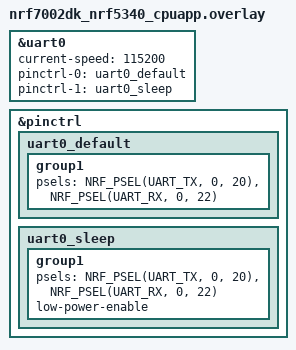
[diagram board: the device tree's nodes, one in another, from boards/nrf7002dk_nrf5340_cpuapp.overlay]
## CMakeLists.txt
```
cmake_minimum_required(VERSION 3.20.0)

find_package(Zephyr REQUIRED HINTS $ENV{ZEPHYR_BASE})
project(nrf7002_sniffer)

# Dodajemy pliki źródłowe
target_sources(app PRIVATE 
    src/main.cpp 
    src/wifi_scanner.c 
    src/ble_scanner.c
)

# Nagłówki
target_include_directories(app PRIVATE 
    ${CMAKE_CURRENT_SOURCE_DIR}/src 
    ${CMAKE_CURRENT_SOURCE_DIR}/../common/include
)

# Biblioteka OpenDroneID
add_subdirectory(${CMAKE_CURRENT_SOURCE_DIR}/../common/lib/opendroneid build_opendroneid)
target_link_libraries(app PRIVATE opendroneid_lib)
```

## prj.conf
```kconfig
# --- Konfiguracja Systemowa ---
CONFIG_CPP=y
CONFIG_STD_CPP20=y
CONFIG_NEWLIB_LIBC=y
CONFIG_FPU=y

# --- Bluetooth ---
CONFIG_BT=y
CONFIG_BT_OBSERVER=y
CONFIG_BT_EXT_ADV=y

# To jest "magiczna" flaga dla nRF5340, która włącza komunikację z rdzeniem sieciowym
# i automatycznie ustawi wszystkie potrzebne parametry (w tym HCI)
CONFIG_BT_HCI_IPC=y

# Opcjonalne, ale pomocne
CONFIG_BT_DEVICE_NAME="nRF7002_Sniffer"

# --- Wi-Fi (nRF7002 + WPA Supplicant) ---
CONFIG_WIFI=y
CONFIG_WIFI_NRF700X=y
CONFIG_WPA_SUPP=y
CONFIG_NET_L2_WIFI_MGMT=y

CONFIG_WIFI_MGMT_RAW_SCAN_RESULTS=y
CONFIG_WIFI_MGMT_RAW_SCAN_RESULT_LENGTH=512

# Włączamy zaawansowane funkcje, które widnieją w Twoim Kconfig
CONFIG_WPA_SUPP_ADVANCED_FEATURES=y
CONFIG_WPA_SUPP_AP=y

# Networking
CONFIG_NETWORKING=y
CONFIG_NET_NATIVE=y
CONFIG_NET_L2_ETHERNET=y
CONFIG_NET_MGMT=y
CONFIG_NET_MGMT_EVENT=y

# Pamięć (zwiększona zgodnie z Twoim Kconfig dla trybu AP/Supplicant)
CONFIG_COMMON_LIBC_MALLOC_ARENA_SIZE=40000
CONFIG_MAIN_STACK_SIZE=8192
CONFIG_SYSTEM_WORKQUEUE_STACK_SIZE=4096
CONFIG_NET_MGMT_EVENT_STACK_SIZE=4200

# --- Komunikacja ---
CONFIG_SERIAL=y
CONFIG_UART_ASYNC_API=y
CONFIG_PRINTK=y

CONFIG_WIFI_MGMT_SCAN_SSID_FILT_MAX=1
CONFIG_MAIN_STACK_SIZE=8192
```

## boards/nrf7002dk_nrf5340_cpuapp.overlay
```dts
&uart0 {
    status = "okay";
    current-speed = <115200>;
    /* Musimy podać oba stany, bo tego oczekuje definicja nRF5340 */
    pinctrl-0 = <&uart0_default>;
    pinctrl-1 = <&uart0_sleep>;
    pinctrl-names = "default", "sleep";
};

&pinctrl {
    uart0_default: uart0_default {
        group1 {
            psels = <NRF_PSEL(UART_TX, 0, 20)>,
                    <NRF_PSEL(UART_RX, 0, 22)>;
        };
    };

    /* Dodajemy definicję dla trybu uśpienia (wymagane) */
    uart0_sleep: uart0_sleep {
        group1 {
            psels = <NRF_PSEL(UART_TX, 0, 20)>,
                    <NRF_PSEL(UART_RX, 0, 22)>;
            low-power-enable;
        };
    };
};
```

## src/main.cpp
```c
#include <zephyr/kernel.h>
#include <zephyr/drivers/uart.h>
#include <zephyr/sys/printk.h>
#include <zephyr/bluetooth/bluetooth.h> // DODAJ TO KONIECZNIE
#include <math.h> 
#include "inter_board_protocol.h"
#include "drone_id_types.hpp"

extern "C" {
    int start_wifi_sniffer(void);
    int start_ble_sniffer(void);
}

static const struct device *uart_brain = DEVICE_DT_GET(DT_NODELABEL(uart0));
K_MUTEX_DEFINE(uart_mutex);

/**
 * @brief Szacowanie odległości na podstawie RSSI.
 * @note To jest model log-distance path loss.
 */
float estimate_distance(int8_t rssi) {
    // Parametry można dostroić doświadczalnie
    float rssi_at_1m = -38.0f; // Typowa wartość dla drona 1m od odbiornika
    float n = 2.2f;            // Współczynnik propagacji (2.0 = próżnia)
    
    if (rssi >= 0) return 0.0f;
    return powf(10.0f, (rssi_at_1m - (float)rssi) / (10.0f * n));
}

/**
 * @brief Funkcja wysyłająca dane do głównego procesora (Brain) przez UART.
 */
extern "C" void send_to_brain(DroneDiscoveryData *data) {
    // 1. Obliczamy zmienne pomocnicze RAZ na początku funkcji
    float dist = estimate_distance(data->rssi);
    const char *proto = (data->protocol_type < 2) ? "Wi-Fi" : "BLE";

    // 2. LOGOWANIE DO KONSOLI (DEBUG)
    // To tutaj decydujesz, jak log wygląda w terminalu
    if (data->latitude != 0) {
        printk("[%s] DRONE DETECTED! | SN: %s | GPS: %.6f, %.6f | Alt: %.1fm | Dist: %.1fm\n",
               proto, data->serial_number, 
               (double)data->latitude / 10000000.0, 
               (double)data->longitude / 10000000.0,
               (double)data->altitude_msl / 100.0, 
               (double)dist);
    } else {
        // Log dla zwykłych sygnałów (tutaj będzie widać Twojego producenta i MAC)
        printk("[%s] Signal | ID: %s | RSSI: %d dBm | Dist: %.1fm\n", 
               proto, data->serial_number, data->rssi, (double)dist);
    }

    // 3. WYSYŁKA BINARNA DO PROCESORA "BRAIN" (UART)
    IpcHeader header = {
        .magic = PROTOCOL_MAGIC_BYTE,
        .type = MSG_TYPE_DRONE_DATA,
        .length = sizeof(DroneDiscoveryData)
    };
    
    uint8_t checksum = calculate_checksum((const uint8_t*)data, sizeof(DroneDiscoveryData));
    
    // if (k_mutex_lock(&uart_mutex, K_MSEC(100)) == 0) {
    //     uart_tx(uart_brain, (uint8_t*)&header, sizeof(header), SYS_FOREVER_US);
    //     k_busy_wait(1000); 
    //     uart_tx(uart_brain, (uint8_t*)data, sizeof(DroneDiscoveryData), SYS_FOREVER_US);
    //     k_busy_wait(2000);
    //     uart_tx(uart_brain, &checksum, 1, SYS_FOREVER_US);
    //     k_mutex_unlock(&uart_mutex);
    // }
}

int main(void) {
    k_msleep(1000);
    printk("\n--- nRF7002 RemoteID Sniffer v2.2 ---\n");

    if (!device_is_ready(uart_brain)) {
        printk("BŁĄD: UART brain nie jest gotowy!\n");
        return -1;
    }

    // Inicjalizacja Bluetooth przed snifferem!
    int bt_err = bt_enable(NULL);
    if (bt_err) {
        printk("BŁĄD: Inicjalizacja BT nieudana: %d\n", bt_err);
    } else {
        printk("Bluetooth OK.\n");
    }

    start_ble_sniffer();
    start_wifi_sniffer();

    printk("Skanowanie rozpoczęte...\n");

    while (1) { k_msleep(5000); }
}
```

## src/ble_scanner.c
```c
#include <zephyr/bluetooth/bluetooth.h>
#include <zephyr/bluetooth/hci.h>
#include <zephyr/sys/printk.h>
#include <stdio.h>
#include <string.h>
#include "drone_id_types.hpp"
#include <opendroneid.h>

extern void send_to_brain(struct DroneDiscoveryData *data);

// Musimy ją mieć też tutaj (lub w osobnym pliku .h)
static const char* identify_manufacturer(const uint8_t *mac) {
    // 1. Bit losowości - sprawdzamy na końcu, żeby najpierw spróbować dopasować realne OUI
    // (Niektóre firmy używają wielu zakresów, w tym nietypowych)

    // --- DRONY I KONTROLERY ---
    if (mac[0] == 0x60 && mac[1] == 0x60 && mac[2] == 0x1F) return "DJI";
    if (mac[0] == 0x00 && mac[1] == 0x26 && mac[2] == 0x7E) return "DJI";
    if (mac[0] == 0x34 && mac[1] == 0xD2 && mac[2] == 0x62) return "DJI (Mavic)";
    if (mac[0] == 0x00 && mac[1] == 0xE0 && mac[2] == 0x4C) return "DJI (Realtek-Base)";
    if (mac[0] == 0x00 && mac[1] == 0x12 && mac[2] == 0x1C) return "Parrot";
    if (mac[0] == 0x90 && mac[1] == 0x03 && mac[2] == 0xB7) return "Parrot (Skycontroller)";
    if (mac[0] == 0x00 && mac[1] == 0x0B && mac[2] == 0xE5) return "Autel Robotics";
    if (mac[0] == 0x08 && mac[1] == 0xD5 && mac[2] == 0x39) return "FIMI (Xiaomi)";
    if (mac[0] == 0x40 && mac[1] == 0x15 && mac[2] == 0xFF) return "Hubsan";
    if (mac[0] == 0x10 && mac[1] == 0x04 && mac[2] == 0xB8) return "Skydio";
    if (mac[0] == 0x04 && mac[1] == 0xEE && mac[2] == 0x03) return "Yuneec";

    // --- SPRZĘT MOBILNY / TELEFONY ---
    // Apple (częste zakresy)
    if (mac[0] == 0xAC && mac[1] == 0x3C && mac[2] == 0x0B) return "Apple (iPhone)";
    if (mac[0] == 0xF0 && mac[1] == 0x18 && mac[2] == 0x98) return "Apple";
    if (mac[0] == 0x8C && mac[1] == 0x85 && mac[2] == 0x90) return "Apple";
    
    // Samsung
    if (mac[0] == 0x3E && mac[1] == 0x36 && mac[2] == 0xF0) return "Samsung";
    if (mac[0] == 0x50 && mac[1] == 0x85 && mac[2] == 0x69) return "Samsung";
    if (mac[0] == 0x24 && mac[1] == 0xFC && mac[2] == 0xE5) return "Samsung";

    // Xiaomi / Huawei / Oppo
    if (mac[0] == 0x64 && mac[1] == 0x09 && mac[2] == 0x80) return "Xiaomi";
    if (mac[0] == 0x28 && mac[1] == 0x6D && mac[2] == 0xCD) return "Xiaomi";
    if (mac[0] == 0x40 && mac[1] == 0x4D && mac[2] == 0x7F) return "Huawei";
    if (mac[0] == 0x34 && mac[1] == 0xCE && mac[2] == 0x00) return "Huawei";

    // --- MODUŁY I IOT (Dla dłubaczy dornów DIY) ---
    if (mac[0] == 0x24 && mac[1] == 0xA5 && mac[2] == 0x2C) return "Espressif (ESP32)";
    if (mac[0] == 0x30 && mac[1] == 0xAE && mac[2] == 0xA4) return "Espressif (ESP32)";
    if (mac[0] == 0xDC && mac[1] == 0xA6 && mac[2] == 0x32) return "Raspberry Pi";
    if (mac[0] == 0xB8 && mac[1] == 0x27 && mac[2] == 0xEB) return "Raspberry Pi";
    if (mac[0] == 0xE8 && mac[1] == 0x31 && mac[2] == 0xCD) return "Linksys/Cisco";
    if (mac[0] == 0x00 && mac[1] == 0x50 && mac[2] == 0x43) return "Marvell (często drony)";

    // --- CHECK BITU LOSOWOŚCI (LAA) ---
    if ((mac[0] & 0x02) == 0x02) return "Mobile/Random";

    return "Unknown";
}

struct ble_parse_context {
    struct DroneDiscoveryData *drone_data;
    bool name_found;
    bool rid_found;
};

static bool ble_ad_cb(struct bt_data *data, void *user_data) {
    struct ble_parse_context *ctx = (struct ble_parse_context *)user_data;

    // 1. Nazwa urządzenia (Active Scan Response)
    if ((data->type == BT_DATA_NAME_COMPLETE || data->type == BT_DATA_NAME_SHORTENED)) {
        char temp_name[16];
        size_t name_len = MIN(data->data_len, sizeof(temp_name) - 1);
        memcpy(temp_name, data->data, name_len);
        temp_name[name_len] = '\0';
        
        // Bezpieczne łączenie: Nazwa + to co już jest w serial_number (np. końcówka MAC)
        // Zakładamy, że w serial_number mamy już "Producent MAC" z device_found
        char current_id[21];
        strncpy(current_id, ctx->drone_data->serial_number, sizeof(current_id)-1);

        snprintf(ctx->drone_data->serial_number, 21, "%.10s [%.7s]", temp_name, current_id);
        ctx->name_found = true;
    }

    // 2. Remote ID (ASTM F3411)
    if (data->type == BT_DATA_SVC_DATA16 && data->data_len >= 3) {
        uint16_t svc_uuid = (data->data[1] << 8) | data->data[0];
        if (svc_uuid == 0xFFFA) {
            ODID_UAS_Data UAS_data;
            odid_initUasData(&UAS_data);
            
            if (decodeOpenDroneID(&UAS_data, data->data + 2) != ODID_MESSAGETYPE_INVALID) {
                if (UAS_data.LocationValid) {
                    ctx->drone_data->latitude = (int32_t)(UAS_data.Location.Latitude * 10000000.0);
                    ctx->drone_data->longitude = (int32_t)(UAS_data.Location.Longitude * 10000000.0);
                    ctx->drone_data->altitude_msl = (int32_t)(UAS_data.Location.AltitudeGeo * 100);
                    ctx->drone_data->speed_horizontal = (int16_t)(UAS_data.Location.SpeedHorizontal * 100);
                    ctx->drone_data->track_direction = (int16_t)UAS_data.Location.Direction;
                    
                    // Jeśli to dron, nadpisujemy numerem seryjnym RID (najważniejsza informacja)
                    snprintf(ctx->drone_data->serial_number, 21, "R:%.18s", UAS_data.BasicID[0].UASID);
                    ctx->rid_found = true;
                }
            }
        }
    }
    return true;
}

static void device_found(const bt_addr_le_t *addr, int8_t rssi, uint8_t type,
                         struct net_buf_simple *ad)
{
    struct DroneDiscoveryData drone_data = {0};
    struct ble_parse_context ctx = { .drone_data = &drone_data, .name_found = false, .rid_found = false };
    
    const char *vendor = identify_manufacturer(addr->a.val);
    
    // Ustawiamy podstawowy format: "Vendor XX:XX" (bierzemy 2 ostatnie bajty adresu)
    snprintf(drone_data.serial_number, 21, "%s %02X%02X", 
             vendor, addr->a.val[1], addr->a.val[0]);

    bt_data_parse(ad, ble_ad_cb, &ctx);

    drone_data.rssi = rssi;
    drone_data.protocol_type = (type == BT_GAP_ADV_TYPE_ADV_IND) ? 2 : 3; 
    drone_data.timestamp = k_uptime_get_32();
    
    send_to_brain(&drone_data);
}


int start_ble_sniffer(void) {
    // Nie inicjalizuj bt_enable tutaj, skoro robisz to w main.cpp!
    
    struct bt_le_scan_param scan_param = {
        .type       = BT_LE_SCAN_TYPE_ACTIVE,
        // ZMIANA: Dodajemy jawnie obsługę PHY 1M i CODED (drony używają obu)
        .options    = BT_LE_SCAN_OPT_NONE, 
        .interval   = 0x0010, // Szybsze skanowanie (10ms)
        .window     = 0x0010,
    };

    // Upewnij się, że bt_le_scan_start nie zwraca błędu
    int err = bt_le_scan_start(&scan_param, device_found);
    if (err) {
        printk("BŁĄD startu skanowania: %d\n", err);
    }
    return err;
}
```

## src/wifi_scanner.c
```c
#ifndef CONFIG_WIFI_MGMT_SCAN_SSID_ADVANCED
#define CONFIG_WIFI_MGMT_SCAN_SSID_ADVANCED 1
#endif

#include <zephyr/kernel.h>
#include <zephyr/net/wifi_mgmt.h>
#include <zephyr/net/net_mgmt.h>
#include <zephyr/net/net_if.h>
#include <stdio.h>
#include <string.h>
#include "drone_id_types.hpp"
#include <opendroneid.h> 

extern void send_to_brain(struct DroneDiscoveryData *data);

// DEFINICJA MUSI BYĆ NA GÓRZE
static const char* identify_manufacturer(const uint8_t *mac) {
    // 1. Bit losowości - sprawdzamy na końcu, żeby najpierw spróbować dopasować realne OUI
    // (Niektóre firmy używają wielu zakresów, w tym nietypowych)

    // --- DRONY I KONTROLERY ---
    if (mac[0] == 0x60 && mac[1] == 0x60 && mac[2] == 0x1F) return "DJI";
    if (mac[0] == 0x00 && mac[1] == 0x26 && mac[2] == 0x7E) return "DJI";
    if (mac[0] == 0x34 && mac[1] == 0xD2 && mac[2] == 0x62) return "DJI (Mavic)";
    if (mac[0] == 0x00 && mac[1] == 0xE0 && mac[2] == 0x4C) return "DJI (Realtek-Base)";
    if (mac[0] == 0x00 && mac[1] == 0x12 && mac[2] == 0x1C) return "Parrot";
    if (mac[0] == 0x90 && mac[1] == 0x03 && mac[2] == 0xB7) return "Parrot (Skycontroller)";
    if (mac[0] == 0x00 && mac[1] == 0x0B && mac[2] == 0xE5) return "Autel Robotics";
    if (mac[0] == 0x08 && mac[1] == 0xD5 && mac[2] == 0x39) return "FIMI (Xiaomi)";
    if (mac[0] == 0x40 && mac[1] == 0x15 && mac[2] == 0xFF) return "Hubsan";
    if (mac[0] == 0x10 && mac[1] == 0x04 && mac[2] == 0xB8) return "Skydio";
    if (mac[0] == 0x04 && mac[1] == 0xEE && mac[2] == 0x03) return "Yuneec";

    // --- SPRZĘT MOBILNY / TELEFONY ---
    // Apple (częste zakresy)
    if (mac[0] == 0xAC && mac[1] == 0x3C && mac[2] == 0x0B) return "Apple (iPhone)";
    if (mac[0] == 0xF0 && mac[1] == 0x18 && mac[2] == 0x98) return "Apple";
    if (mac[0] == 0x8C && mac[1] == 0x85 && mac[2] == 0x90) return "Apple";
    
    // Samsung
    if (mac[0] == 0x3E && mac[1] == 0x36 && mac[2] == 0xF0) return "Samsung";
    if (mac[0] == 0x50 && mac[1] == 0x85 && mac[2] == 0x69) return "Samsung";
    if (mac[0] == 0x24 && mac[1] == 0xFC && mac[2] == 0xE5) return "Samsung";

    // Xiaomi / Huawei / Oppo
    if (mac[0] == 0x64 && mac[1] == 0x09 && mac[2] == 0x80) return "Xiaomi";
    if (mac[0] == 0x28 && mac[1] == 0x6D && mac[2] == 0xCD) return "Xiaomi";
    if (mac[0] == 0x40 && mac[1] == 0x4D && mac[2] == 0x7F) return "Huawei";
    if (mac[0] == 0x34 && mac[1] == 0xCE && mac[2] == 0x00) return "Huawei";

    // --- MODUŁY I IOT (Dla dłubaczy dornów DIY) ---
    if (mac[0] == 0x24 && mac[1] == 0xA5 && mac[2] == 0x2C) return "Espressif (ESP32)";
    if (mac[0] == 0x30 && mac[1] == 0xAE && mac[2] == 0xA4) return "Espressif (ESP32)";
    if (mac[0] == 0xDC && mac[1] == 0xA6 && mac[2] == 0x32) return "Raspberry Pi";
    if (mac[0] == 0xB8 && mac[1] == 0x27 && mac[2] == 0xEB) return "Raspberry Pi";
    if (mac[0] == 0xE8 && mac[1] == 0x31 && mac[2] == 0xCD) return "Linksys/Cisco";
    if (mac[0] == 0x00 && mac[1] == 0x50 && mac[2] == 0x43) return "Marvell (często drony)";

    // --- CHECK BITU LOSOWOŚCI (LAA) ---
    if ((mac[0] & 0x02) == 0x02) return "Mobile/Random";

    return "Unknown";
}


static void wifi_mgmt_event_handler(struct net_mgmt_event_callback *cb,
                                    uint32_t mgmt_event, struct net_if *iface)
{
    // Obsługa surowych danych (tu są dane Remote ID)
    if (mgmt_event == NET_EVENT_WIFI_RAW_SCAN_RESULT) {
        const struct wifi_raw_scan_result *raw = (const struct wifi_raw_scan_result *)cb->info;
        struct DroneDiscoveryData drone_data = {0};
        
        drone_data.rssi = raw->rssi;
        drone_data.protocol_type = 0; 
        drone_data.timestamp = k_uptime_get_32();

        printk("RAW Frame recvd: len %d, RSSI %d\n", raw->frame_length, raw->rssi);

        ODID_UAS_Data UAS_data;
        odid_initUasData(&UAS_data);

        // Przetwarzamy surową ramkę (raw->data) o długości raw->frame_length
        // odid_message_process_pack przeszuka ramkę w poszukiwaniu elementów Remote ID
        if (odid_message_process_pack(&UAS_data, raw->data, raw->frame_length) >= 0) {
            if (UAS_data.LocationValid) {
                snprintf(drone_data.serial_number, sizeof(drone_data.serial_number), "R:%s", UAS_data.BasicID[0].UASID);
                drone_data.latitude = (int32_t)(UAS_data.Location.Latitude * 10000000.0);
                drone_data.longitude = (int32_t)(UAS_data.Location.Longitude * 10000000.0);
                drone_data.altitude_msl = (int32_t)(UAS_data.Location.AltitudeGeo * 100);
                drone_data.speed_horizontal = (int16_t)(UAS_data.Location.SpeedHorizontal * 100);
                drone_data.track_direction = (int16_t)UAS_data.Location.Direction;
                send_to_brain(&drone_data);
            }
        }
    }
    // Obsługa standardowego wyniku (dla wyświetlania urządzeń nie-dronów)
else if (mgmt_event == NET_EVENT_WIFI_SCAN_RESULT) {
        const struct wifi_scan_result *res = (const struct wifi_scan_result *)cb->info;
        struct DroneDiscoveryData drone_data = {0};
        
        const char *vendor = identify_manufacturer(res->mac);
        
        // ZAPISUJEMY: Nazwa + 3 ostatnie bajty MAC dla unikalności
        snprintf(drone_data.serial_number, sizeof(drone_data.serial_number), 
         "%.10s %02X%02X%02X%02X", 
         vendor, res->mac[2], res->mac[3], res->mac[4], res->mac[5]);  
        
        drone_data.rssi = res->rssi;
        drone_data.protocol_type = 0;
        drone_data.timestamp = k_uptime_get_32();
        
        send_to_brain(&drone_data);
    }
    else if (mgmt_event == NET_EVENT_WIFI_SCAN_DONE) {
        k_sleep(K_MSEC(1000));
        struct wifi_scan_params params = { .scan_type = WIFI_SCAN_TYPE_PASSIVE };
        net_mgmt(NET_REQUEST_WIFI_SCAN, iface, &params, sizeof(params));
    }
}

static struct net_mgmt_event_callback wifi_cb;

int start_wifi_sniffer(void) {
    struct net_if *iface = net_if_get_default();
    
    // REJESTRUJEMY TRZY ZDARZENIA: RAW, RESULT i DONE
    net_mgmt_init_event_callback(&wifi_cb, wifi_mgmt_event_handler, 
                                 NET_EVENT_WIFI_SCAN_RESULT | 
                                 NET_EVENT_WIFI_RAW_SCAN_RESULT | 
                                 NET_EVENT_WIFI_SCAN_DONE);
    net_mgmt_add_event_callback(&wifi_cb);
    
    struct wifi_scan_params params = { .scan_type = WIFI_SCAN_TYPE_PASSIVE };
    return net_mgmt(NET_REQUEST_WIFI_SCAN, iface, &params, sizeof(params));
}
```
